VERSION ""

NS_ :

BS_:

BU_:

BO_ 8 Accelerated_Speed: 4 Vector__XXX
 SG_ Accelerated : 0|32@1- (1,0) [0|0] "" Vector__XXX

BO_ 7 EnviromentTempAndHumi: 4 Vector__XXX
 SG_ En_Temperature : 16|16@1+ (0.005,-200) [-100|200] "¡æ" Vector__XXX
 SG_ En_Humidity : 0|16@1+ (0.005,-200) [-100|200] "RH%" Vector__XXX

BO_ 6 Channel6Current: 8 Vector__XXX
 SG_ CurrentSig : 0|32@1- (1,0) [-10|10] "A" Vector__XXX

BO_ 5 Channel5Current: 8 Vector__XXX
 SG_ CurrentSig : 0|32@1- (1,0) [-10|10] "A" Vector__XXX

BO_ 4 Channel4Current: 8 Vector__XXX
 SG_ CurrentSig : 0|32@1- (1,0) [-10|10] "A" Vector__XXX

BO_ 3 Channel3Current: 8 Vector__XXX
 SG_ CurrentSig : 0|32@1- (1,0) [-10|10] "A" Vector__XXX

BO_ 2 Channel2Current: 8 Vector__XXX
 SG_ CurrentSig : 0|32@1- (1,0) [-10|10] "A" Vector__XXX

BO_ 1 Channel1Current: 8 Vector__XXX
 SG_ CurrentSig : 0|32@1- (1,0) [-10|10] "A" Vector__XXX

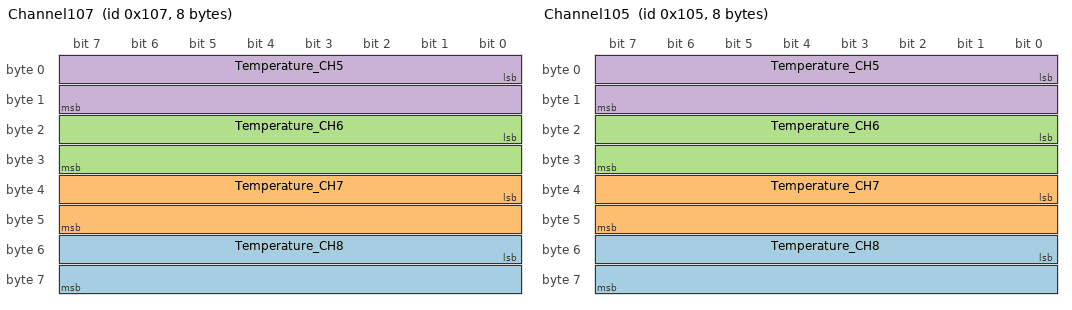
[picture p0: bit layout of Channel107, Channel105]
BO_ 263 Channel107: 8 Vector__XXX
 SG_ Temperature_CH8 : 48|16@1+ (0.005,-200) [-100|200] "¡æ" Vector__XXX
 SG_ Temperature_CH7 : 32|16@1+ (0.005,-200) [-100|200] "¡æ" Vector__XXX
 SG_ Temperature_CH6 : 16|16@1+ (0.005,-200) [-100|200] "¡æ" Vector__XXX
 SG_ Temperature_CH5 : 0|16@1+ (0.005,-200) [-100|200] "¡æ" Vector__XXX

BO_ 261 Channel105: 8 Vector__XXX
 SG_ Temperature_CH8 : 48|16@1+ (0.005,-200) [-100|200] "¡æ" Vector__XXX
 SG_ Temperature_CH7 : 32|16@1+ (0.005,-200) [-100|200] "¡æ" Vector__XXX
 SG_ Temperature_CH6 : 16|16@1+ (0.005,-200) [-100|200] "¡æ" Vector__XXX
 SG_ Temperature_CH5 : 0|16@1+ (0.005,-200) [-100|200] "¡æ" Vector__XXX

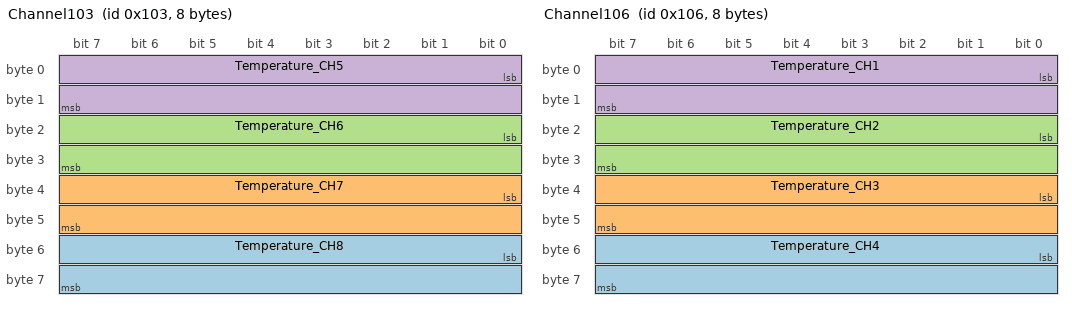
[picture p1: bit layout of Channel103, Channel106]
BO_ 259 Channel103: 8 Vector__XXX
 SG_ Temperature_CH8 : 48|16@1+ (0.005,-200) [-100|200] "¡æ" Vector__XXX
 SG_ Temperature_CH7 : 32|16@1+ (0.005,-200) [-100|200] "¡æ" Vector__XXX
 SG_ Temperature_CH6 : 16|16@1+ (0.005,-200) [-100|200] "¡æ" Vector__XXX
 SG_ Temperature_CH5 : 0|16@1+ (0.005,-200) [-100|200] "¡æ" Vector__XXX

BO_ 262 Channel106: 8 Vector__XXX
 SG_ Temperature_CH4 : 48|16@1+ (0.005,-200) [-100|200] "¡æ" Vector__XXX
 SG_ Temperature_CH3 : 32|16@1+ (0.005,-200) [-100|200] "¡æ" Vector__XXX
 SG_ Temperature_CH2 : 16|16@1+ (0.005,-200) [-100|200] "¡æ" Vector__XXX
 SG_ Temperature_CH1 : 0|16@1+ (0.005,-200) [-100|200] "¡æ" Vector__XXX

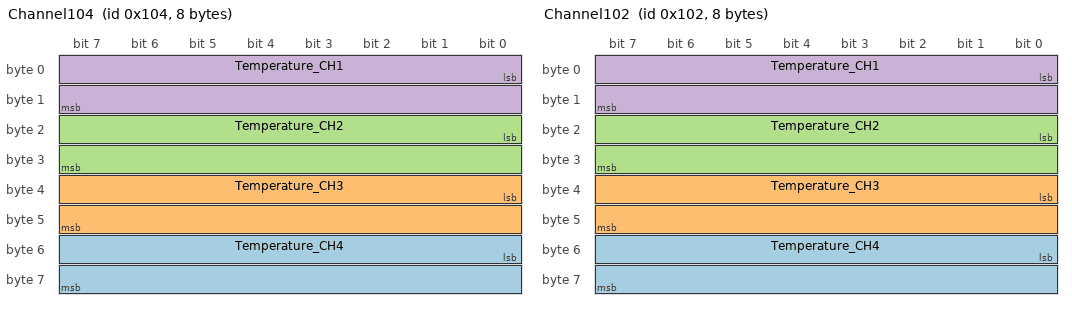
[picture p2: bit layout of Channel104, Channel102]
BO_ 260 Channel104: 8 Vector__XXX
 SG_ Temperature_CH4 : 48|16@1+ (0.005,-200) [-100|200] "¡æ" Vector__XXX
 SG_ Temperature_CH3 : 32|16@1+ (0.005,-200) [-100|200] "¡æ" Vector__XXX
 SG_ Temperature_CH2 : 16|16@1+ (0.005,-200) [-100|200] "¡æ" Vector__XXX
 SG_ Temperature_CH1 : 0|16@1+ (0.005,-200) [-100|200] "¡æ" Vector__XXX

BO_ 258 Channel102: 8 Vector__XXX
 SG_ Temperature_CH4 : 48|16@1+ (0.005,-200) [-100|200] "¡æ" Vector__XXX
 SG_ Temperature_CH3 : 32|16@1+ (0.005,-200) [-100|200] "¡æ" Vector__XXX
 SG_ Temperature_CH2 : 16|16@1+ (0.005,-200) [-100|200] "¡æ" Vector__XXX
 SG_ Temperature_CH1 : 0|16@1+ (0.005,-200) [-100|200] "¡æ" Vector__XXX

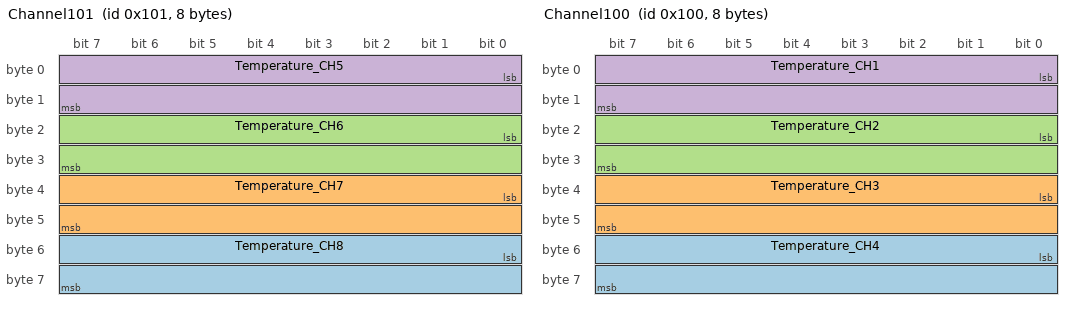
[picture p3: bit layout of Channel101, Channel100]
BO_ 257 Channel101: 8 Vector__XXX
 SG_ Temperature_CH8 : 48|16@1+ (0.005,-200) [-100|200] "¡æ" Vector__XXX
 SG_ Temperature_CH7 : 32|16@1+ (0.005,-200) [-100|200] "¡æ" Vector__XXX
 SG_ Temperature_CH6 : 16|16@1+ (0.005,-200) [-100|200] "¡æ" Vector__XXX
 SG_ Temperature_CH5 : 0|16@1+ (0.005,-200) [-100|200] "¡æ" Vector__XXX

BO_ 256 Channel100: 8 Vector__XXX
 SG_ Temperature_CH4 : 48|16@1+ (0.005,-200) [-100|200] "¡æ" Vector__XXX
 SG_ Temperature_CH3 : 32|16@1+ (0.005,-200) [-100|200] "¡æ" Vector__XXX
 SG_ Temperature_CH2 : 16|16@1+ (0.005,-200) [-100|200] "¡æ" Vector__XXX
 SG_ Temperature_CH1 : 0|16@1+ (0.005,-200) [-100|200] "¡æ" Vector__XXX

BA_DEF_ SG_  "GenSigSendType" ENUM  "Cyclic","OnWrite","OnWriteWithRepetition","OnChange","OnChangeWithRepetition","IfActive","IfActiveWithRepetition","NoSigSendType";
BA_DEF_ BO_  "GenMsgSendType" ENUM  "Cyclic","not_used","not_used","not_used","not_used","Cyclic","not_used","IfActive","NoMsgSendType";
BA_DEF_  "DBName" STRING ;
BA_DEF_  "BusType" STRING ;
BA_DEF_DEF_  "GenSigSendType" "Cyclic";
BA_DEF_DEF_  "GenMsgSendType" "NoMsgSendType";
BA_DEF_DEF_  "DBName" "";
BA_DEF_DEF_  "BusType" "CAN";
BA_ "DBName" "TS_ThermoCouple";
SIG_VALTYPE_ 8 Accelerated : 1;
SIG_VALTYPE_ 6 CurrentSig : 1;
SIG_VALTYPE_ 5 CurrentSig : 1;
SIG_VALTYPE_ 4 CurrentSig : 1;
SIG_VALTYPE_ 3 CurrentSig : 1;
SIG_VALTYPE_ 2 CurrentSig : 1;
SIG_VALTYPE_ 1 CurrentSig : 1;
